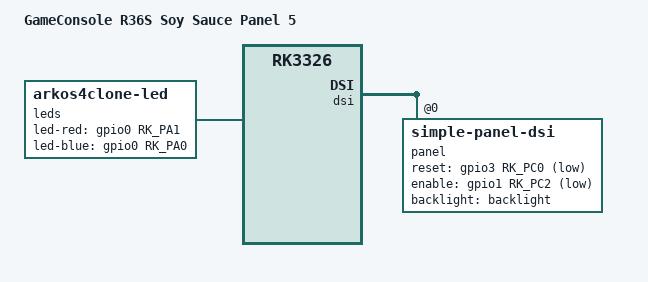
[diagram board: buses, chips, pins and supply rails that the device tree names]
// SPDX-License-Identifier: (GPL-2.0+ OR MIT)
/*
* Copyright (c) 2026 kk&lcdyk
*
* R36S 酱油 Panel 5
*
*/

/dts-v1/;
#include "rk3326-r36s-sauce.dtsi"

/ {
	model = "GameConsole R36S Soy Sauce Panel 5";
	compatible = "rockchip,rk3326-r36s-sauce-panel5-linux","rockchip,rk3326";
	
	leds: arkos4clone-leds {
		compatible = "arkos4clone-led";
		
		led-red = <&gpio0 RK_PA1 GPIO_ACTIVE_HIGH>;
		led-blue = <&gpio0 RK_PA0 GPIO_ACTIVE_HIGH>;
	};
};

&dsi {
	status = "okay";
	
	panel@0 {
		compatible = "simple-panel-dsi";
		reg = <0>;
		/* pwm1 backlight */
		backlight = <&backlight>;
		/* LCD reset gpio GPIO3.B7 */
		reset-gpios = <&gpio3 RK_PC0 GPIO_ACTIVE_LOW>;
		/* power-supply-gpio GPIO0.B5  */
		enable-gpios = <&gpio1 RK_PC2 GPIO_ACTIVE_LOW>;
		prepare-delay-ms = <100>;
		reset-delay-ms = <100>;
		init-delay-ms = <20>;
		enable-delay-ms = <200>;
		disable-delay-ms = <200>;
		unprepare-delay-ms = <20>;
		width-mm = <153>;
		height-mm = <85>;
		dsi,flags  = <(MIPI_DSI_MODE_VIDEO |
		MIPI_DSI_MODE_VIDEO_BURST |
		MIPI_DSI_MODE_LPM |
		MIPI_DSI_MODE_EOT_PACKET)>;
		dsi,format = <MIPI_DSI_FMT_RGB888>;
		dsi,lanes = <4>;
		panel-init-sequence = [39 00 04 b9 f1 12 87 39 00 04 b2 78 04 70 39 00 0b b3 10 10 fc fc 03 ff 00 00 00 00 15 00 02 b4 80 39 00 03 b5 0f 0f 39 00 03 b6 70 70 39 00 05 b8 26 22 f0 13 39 00 1c ba 33 81 05 f9 0e 0e 20 00 00 00 00 00 00 00 44 25 00 91 0a 00 00 01 4f 01 00 00 37 15 00 02 bc 47 39 00 06 bf 02 11 00 80 04 39 00 0a c0 73 73 50 50 00 00 12 73 00 39 00 12 c1 73 00 32 32 77 f4 77 77 cc cc ff ff 11 11 00 00 32 39 00 0d c7 b8 00 0a 10 01 09 00 00 ed c5 00 a5 39 00 05 c8 10 40 1e 03 15 00 02 cc 0b 39 00 23 e0 00 05 09 29 3c 3f 3b 37 05 0a 0c 10 13 10 13 12 1a 00 05 09 29 3c 3f 3b 37 05 0a 0c 10 13 10 13 12 1a 39 00 08 e1 11 11 91 00 00 00 00 39 00 0f e3 07 07 0b 0b 0b 0b 00 00 00 00 ff 04 c0 10 39 00 40 e9 c8 10 02 00 00 b0 b1 11 31 23 28 80 b0 b1 27 08 00 04 02 00 00 00 00 04 02 00 00 00 88 88 ba 60 24 08 88 88 88 88 88 88 88 ba 71 35 18 88 88 88 88 88 00 00 00 01 00 00 00 00 00 00 00 00 00 39 00 3e ea 97 0a 82 02 03 07 00 00 00 00 00 00 81 88 ba 17 53 88 88 88 88 88 88 80 88 ba 06 42 88 88 88 88 88 88 23 00 00 02 a5 00 00 00 00 00 00 00 00 00 00 00 00 00 00 00 00 00 00 00 00 00 00 39 00 04 ef ff ff 01 05 fa 01 11 05 32 01 29];
		panel-exit-sequence = <0x5780128 0x5780110>;
		
		display-timings {
			native-mode = <&timing0>;
			
			// 40.00MHz / (640+46+2+44)×(480+16+2+14) = 732×512 = 106.73 Hz
			timing0: original {
				clock-frequency = <40000000>;
				hactive = <640>;
				vactive = <480>;
				hback-porch = <44>;
				hfront-porch = <46>;
				vback-porch = <14>;
				vfront-porch = <16>;
				hsync-len = <2>;
				vsync-len = <2>;
				hsync-active = <0>;
				vsync-active = <0>;
				de-active = <0>;
				pixelclk-active = <0>;
			};
		};
	};
};

&rk817 {
    charger {
        chg_led_gpio = <&gpio0 RK_PA5 GPIO_ACTIVE_HIGH>;
    };
};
